# STM32U366 register map
File version: 1.0
CPU: CM33 r0p1, little endian, MPU, FPU, 4 interrupt priority bits
Registers are 32-bit, read-write, reset 0x0 unless marked. A register's access mark holds for its fields unless they carry their own. Offsets are from the block's base; [hi:lo] are bit positions; {n}, {i} and the like mark numbered series.

## DBGMCU — DBGMCU Address block
Base 0xE0044000
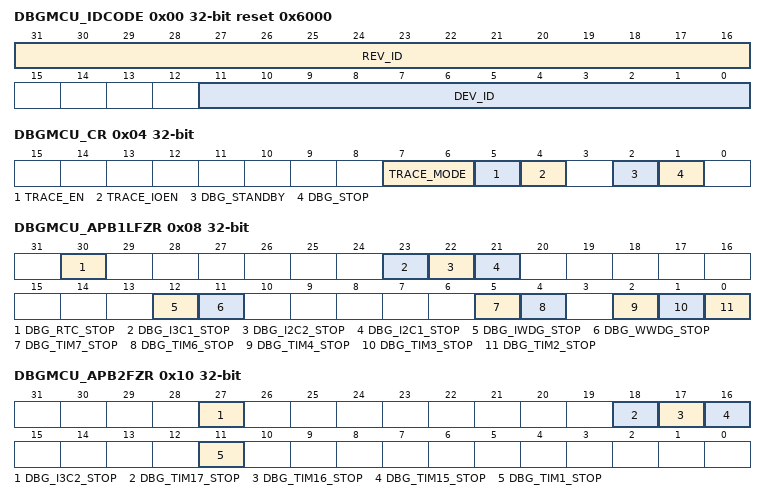
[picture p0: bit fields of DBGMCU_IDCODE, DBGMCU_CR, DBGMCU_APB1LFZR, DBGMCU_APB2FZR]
0x00 DBGMCU_IDCODE ro reset 0x6000 (reset mask 0xF000) — DBGMCU identity code register
  [31:16] REV_ID — None 0x0001: revision A
    1=revision A
  [11:0] DEV_ID — None 0x454: STM32U375/385
    0x454=STM32U375/385
0x04 DBGMCU_CR — DBGMCU configuration register
  [7:6] TRACE_MODE — None 0x0: trace pins assigned for asynchronous mode (TRACESWO) 0x1: trace pins assigned for synchronous mode with a port width of 1 (TRACECK, TRACED0) 0x2: trace pins assigned for synchronous mode with a port width of 2 ((TRACECK, TRACED0-1) 0x3: trace pins assigned for synchronous mode with a port width of 4 ((TRACECK, TRACED0-3)
    0=trace pins assigned for asynchronous mode (TRACESWO); 1=trace pins assigned for synchronous mode with a port width of 1 (TRACECK, TRACED0); 2=trace pins assigned for synchronous mode with a port width of 2 ((TRACECK, TRACED0-1); 3=trace pins assigned for synchronous mode with a port width of 4 ((TRACECK, TRACED0-3)
  [5] TRACE_EN — This bit enables the trace port clock, TRACECK. 0: disabled 1: enabled
    0=disabled; 1=enabled
  [4] TRACE_IOEN — None 0: disabled-trace pins not assigned 1: enabled-trace pins assigned according to the value of TRACE_MODE field
    0=disabled-trace pins not assigned; 1=enabled-trace pins assigned according to the value of TRACE_MODE field
  [2] DBG_STANDBY — All clocks are disabled and the core powered down automatically in Standby mode. All active clocks and oscillators continue to run during Standby mode, and the core supply is maintained, allowing full debug capability. On exit from Standby mode, a system reset is performed. 0: normal operation 1: automatic clock stop/power down disabled
    0=normal operation; 1=automatic clock stop/power down disabled
  [1] DBG_STOP — All clocks are disabled automatically in Stop mode. All active clocks and oscillators continue to run during Stop mode, allowing full debug capability. On exit from Stop mode, the clock settings are set to the Stop mode exit state. 0: normal operation 1: automatic clock stop disabled
    0=normal operation; 1=automatic clock stop disabled
0x08 DBGMCU_APB1LFZR — DBGMCU APB1L peripheral freeze register
  [30] DBG_RTC_STOP — None 0: normal operation. RTC continues to operate while CPU is in debug mode. 1: stop in debug. RTC is frozen while CPU is in debug mode.
    0=normal operation. RTC continues to operate while CPU is in debug mode.; 1=stop in debug. RTC is frozen while CPU is in debug mode.
  [23] DBG_I3C1_STOP — None 0: normal operation. I3C1 timeout continues to operate while CPU is in debug mode. 1: stop in debug. I3C1 timeout is frozen while CPU is in debug mode.
    0=normal operation. I3C1 timeout continues to operate while CPU is in debug mode.; 1=stop in debug. I3C1 timeout is frozen while CPU is in debug mode.
  [22] DBG_I2C2_STOP — None 0: normal operation. I2C2 SMBUS timeout continues to operate while CPU is in debug mode. 1: stop in debug. I2C2 SMBUS timeout is frozen while CPU is in debug mode.
    0=normal operation. I2C2 SMBUS timeout continues to operate while CPU is in debug mode.; 1=stop in debug. I2C2 SMBUS timeout is frozen while CPU is in debug mode.
  [21] DBG_I2C1_STOP — None 0: normal operation. I2C1 SMBUS timeout continues to operate while CPU is in debug mode. 1: stop in debug. I2C1 SMBUS timeout is frozen while CPU is in debug mode.
    0=normal operation. I2C1 SMBUS timeout continues to operate while CPU is in debug mode.; 1=stop in debug. I2C1 SMBUS timeout is frozen while CPU is in debug mode.
  [12] DBG_IWDG_STOP — None 0: normal operation. IWDG continues to operate while CPU is in debug mode. 1: stop in debug. IWDG is frozen while CPU is in debug mode.
    0=normal operation. IWDG continues to operate while CPU is in debug mode.; 1=stop in debug. IWDG is frozen while CPU is in debug mode.
  [11] DBG_WWDG_STOP — None 0: normal operation. WWDG continues to operate while CPU is in debug mode. 1: stop in debug. WWDG is frozen while CPU is in debug mode.
    0=normal operation. WWDG continues to operate while CPU is in debug mode.; 1=stop in debug. WWDG is frozen while CPU is in debug mode.
  [5] DBG_TIM7_STOP — None 0: normal operation. TIM7 continues to operate while CPU is in debug mode. 1: stop in debug. TIM7 is frozen while CPU is in debug mode.
    0=normal operation. TIM7 continues to operate while CPU is in debug mode.; 1=stop in debug. TIM7 is frozen while CPU is in debug mode.
  [4] DBG_TIM6_STOP — None 0: normal operation. TIM6 continues to operate while CPU is in debug mode. 1: stop in debug. TIM6 is frozen while CPU is in debug mode.
    0=normal operation. TIM6 continues to operate while CPU is in debug mode.; 1=stop in debug. TIM6 is frozen while CPU is in debug mode.
  [2] DBG_TIM4_STOP — None 0: normal operation. TIM4 continues to operate while CPU is in debug mode. 1: stop in debug. TIM4 is frozen while CPU is in debug mode.
    0=normal operation. TIM4 continues to operate while CPU is in debug mode.; 1=stop in debug. TIM4 is frozen while CPU is in debug mode.
  [1] DBG_TIM3_STOP — None 0: normal operation. TIM3 continues to operate while CPU is in debug mode. 1: stop in debug. TIM3 is frozen while CPU is in debug mode.
    0=normal operation. TIM3 continues to operate while CPU is in debug mode.; 1=stop in debug. TIM3 is frozen while CPU is in debug mode.
  [0] DBG_TIM2_STOP — None 0: normal operation. TIM2 continues to operate while CPU is in debug mode. 1: stop in debug. TIM2 is frozen while CPU is in debug mode.
    0=normal operation. TIM2 continues to operate while CPU is in debug mode.; 1=stop in debug. TIM2 is frozen while CPU is in debug mode.
0x0C DBGMCU_APB1HFZR — DBGMCU APB1H peripheral freeze register
  [5] DBG_LPTIM2_STOP — None 0: normal operation. LPTIM2 continues to operate while CPU is in debug mode. 1: stop in debug. LPTIM2 is frozen while CPU is in debug mode.
    0=normal operation. LPTIM2 continues to operate while CPU is in debug mode.; 1=stop in debug. LPTIM2 is frozen while CPU is in debug mode.
0x10 DBGMCU_APB2FZR — DBGMCU APB2 peripheral freeze register
  [27] DBG_I3C2_STOP — None 0: normal operation. I3C2 timeout continues to operate while CPU is in debug mode. 1: stop in debug. I3C2 timeout is frozen while CPU is in debug mode.
    0=normal operation. I3C2 timeout continues to operate while CPU is in debug mode.; 1=stop in debug. I3C2 timeout is frozen while CPU is in debug mode.
  [18] DBG_TIM17_STOP — None 0: normal operation. TIM17 continues to operate while CPU is in debug mode. 1: stop in debug. TIM17 is frozen while CPU is in debug mode.
    0=normal operation. TIM17 continues to operate while CPU is in debug mode.; 1=stop in debug. TIM17 is frozen while CPU is in debug mode.
  [17] DBG_TIM16_STOP — None 0: normal operation. TIM16 continues to operate while CPU is in debug mode. 1: stop in debug. TIM16 is frozen while CPU is in debug mode.
    0=normal operation. TIM16 continues to operate while CPU is in debug mode.; 1=stop in debug. TIM16 is frozen while CPU is in debug mode.
  [16] DBG_TIM15_STOP — None 0: normal operation. TIM15 continues to operate while CPU is in debug mode. 1: stop in debug. TIM15 is frozen while CPU is in debug mode.
    0=normal operation. TIM15 continues to operate while CPU is in debug mode.; 1=stop in debug. TIM15 is frozen while CPU is in debug mode.
  [11] DBG_TIM1_STOP — None 0: normal operation. TIM1 continues to operate while CPU is in debug mode. 1: stop in debug. TIM1 is frozen while CPU is in debug mode.
    0=normal operation. TIM1 continues to operate while CPU is in debug mode.; 1=stop in debug. TIM1 is frozen while CPU is in debug mode.
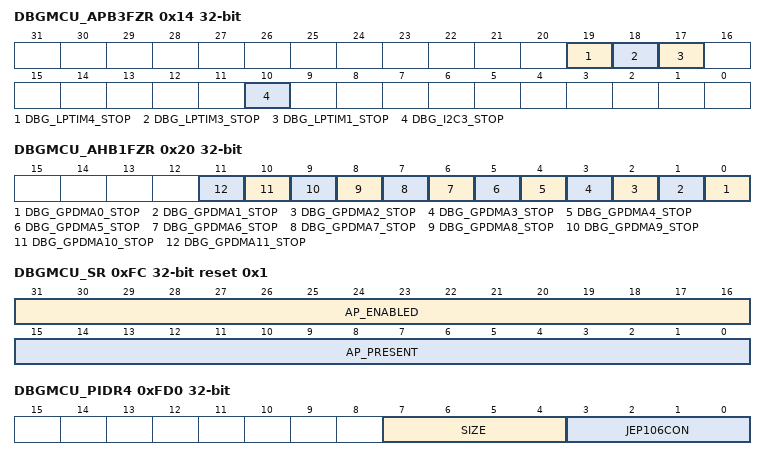
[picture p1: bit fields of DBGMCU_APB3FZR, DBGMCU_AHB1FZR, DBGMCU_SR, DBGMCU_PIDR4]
0x14 DBGMCU_APB3FZR — DBGMCU APB3 peripheral freeze register
  [19] DBG_LPTIM4_STOP — None 0: normal operation. LPTIM4 continues to operate while CPU is in debug mode. 1: stop in debug. LPTIM4 is frozen while CPU is in debug mode.
    0=normal operation. LPTIM4 continues to operate while CPU is in debug mode.; 1=stop in debug. LPTIM4 is frozen while CPU is in debug mode.
  [18] DBG_LPTIM3_STOP — None 0: normal operation. LPTIM3 continues to operate while CPU is in debug mode. 1: stop in debug. LPTIM3 is frozen while CPU is in debug mode.
    0=normal operation. LPTIM3 continues to operate while CPU is in debug mode.; 1=stop in debug. LPTIM3 is frozen while CPU is in debug mode.
  [17] DBG_LPTIM1_STOP — None 0: normal operation. LPTIM1 continues to operate while CPU is in debug mode. 1: stop in debug. LPTIM1 is frozen while CPU is in debug mode.
    0=normal operation. LPTIM1 continues to operate while CPU is in debug mode.; 1=stop in debug. LPTIM1 is frozen while CPU is in debug mode.
  [10] DBG_I2C3_STOP — None 0: normal operation. I2C3 continues to operate while CPU is in debug mode. 1: stop in debug. I2C3 is frozen while CPU is in debug mode.
    0=normal operation. I2C3 continues to operate while CPU is in debug mode.; 1=stop in debug. I2C3 is frozen while CPU is in debug mode.
0x20 DBGMCU_AHB1FZR — DBGMCU AHB1 peripheral freeze register
  [n] DBG_GPDMA{n}_STOP (n=0..11) — None 0: normal operation. GPDMA channel {n} continues to operate while CPU is in debug mode. 1: stop in debug. GPDMA channel {n} is frozen while CPU is in debug mode.
    0=normal operation. GPDMA channel {n} continues to operate while CPU is in debug mode.; 1=stop in debug. GPDMA channel {n} is frozen while CPU is in debug mode.
0xFC DBGMCU_SR wo reset 0x1 (reset mask 0xFFFF00FF) — DBGMCU status register
  [31:16] AP_ENABLED — Bit n=0: APn locked Bit n=1: APn enabled
  [15:0] AP_PRESENT — Bit n=0: APn absent Bit n=1: APn present
0x100 DBGMCU_DBG_AUTH_HOST wo reset not defined — DBGMCU debug host authentication register
  [31:0] AUTH_KEY — The device specific 64-bit authentication key (OEM key) must be written to this register (in two successive 32-bit writes, least significant word first) to permit RDP regression. Writing a wrong key locks access to the device and prevent code execution from the Flash memory.
0x104 DBGMCU_DBG_AUTH_DEVICE ro reset not defined — DBGMCU debug device authentication register
  [31:0] AUTH_ID — Device specific ID used for RDP regression.
0xFD0 DBGMCU_PIDR4 ro — DBGMCU CoreSight peripheral identity register 4
  [7:4] SIZE — None 0x0: The register file occupies a single 4-Kbyte region.
    0=The register file occupies a single 4-Kbyte region
  [3:0] JEP106CON — None 0x0: STMicroelectronics JEDEC code
    0=STMicroelectronics JEDEC code
0xFE0 DBGMCU_PIDR0 ro — DBGMCU CoreSight peripheral identity register 0
  [7:0] PARTNUM — None 0x00: DBGMCU part number
    0=DBGMCU part number
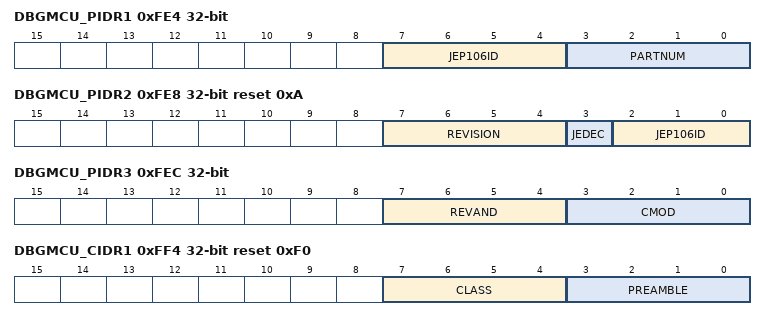
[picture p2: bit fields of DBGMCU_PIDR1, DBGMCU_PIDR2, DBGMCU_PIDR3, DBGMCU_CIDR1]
0xFE4 DBGMCU_PIDR1 ro — DBGMCU CoreSight peripheral identity register 1
  [7:4] JEP106ID — None 0x0: STMicroelectronics JEDEC code
    0=STMicroelectronics JEDEC code
  [3:0] PARTNUM — None 0x0: DBGMCU part number
    0=DBGMCU part number
0xFE8 DBGMCU_PIDR2 ro reset 0xA — DBGMCU CoreSight peripheral identity register 2
  [7:4] REVISION — None 0x0: r0p0
    0=r0p0
  [3] JEDEC — None 0x1: designer identification specified by JEDEC
    1=designer identification specified by JEDEC
  [2:0] JEP106ID — None 0x2: STMicroelectronics JEDEC code
    2=STMicroelectronics JEDEC code
0xFEC DBGMCU_PIDR3 ro — DBGMCU CoreSight peripheral identity register 3
  [7:4] REVAND — None 0x0: no metal fix
    0=no metal fix
  [3:0] CMOD — None 0x0: no customer modifications
    0=no customer modifications
0xFF0 DBGMCU_CIDR0 ro reset 0xD — DBGMCU CoreSight component identity register 0
  [7:0] PREAMBLE — None 0x0D: common identification value
    13=common identification value
0xFF4 DBGMCU_CIDR1 ro reset 0xF0 — DBGMCU CoreSight component identity register 1
  [7:4] CLASS — None 0xF: Non-CoreSight component
    15=Non-CoreSight component
  [3:0] PREAMBLE — None 0x0: common identification value
    0=common identification value
0xFF8 DBGMCU_CIDR2 ro reset 0x5 — DBGMCU CoreSight component identity register 2
  [7:0] PREAMBLE — None 0x05: common identification value
    5=common identification value
0xFFC DBGMCU_CIDR3 ro reset 0xB1 — DBGMCU CoreSight component identity register 3
  [7:0] PREAMBLE — None 0xB1: common identification value
    177=common identification value

## Notices in the file
Copyright (c) 2026 STMicroelectronics.
SPDx-License-Identifier: Apache-2.0
Licensed under the Apache License, Version 2.0 (the "License");
you may not use this file except in compliance with the License.
You may obtain a copy of the License at
http://www.apache.org/licenses/LICENSE-2.0
Unless required by applicable law or agreed to in writing, software
distributed under the License is distributed on an "AS IS" BASIS,
WITHOUT WARRANTIES OR CONDITIONS OF ANY KIND, either express or implied.
See the License for the specific language governing permissions and
limitations under the License.
